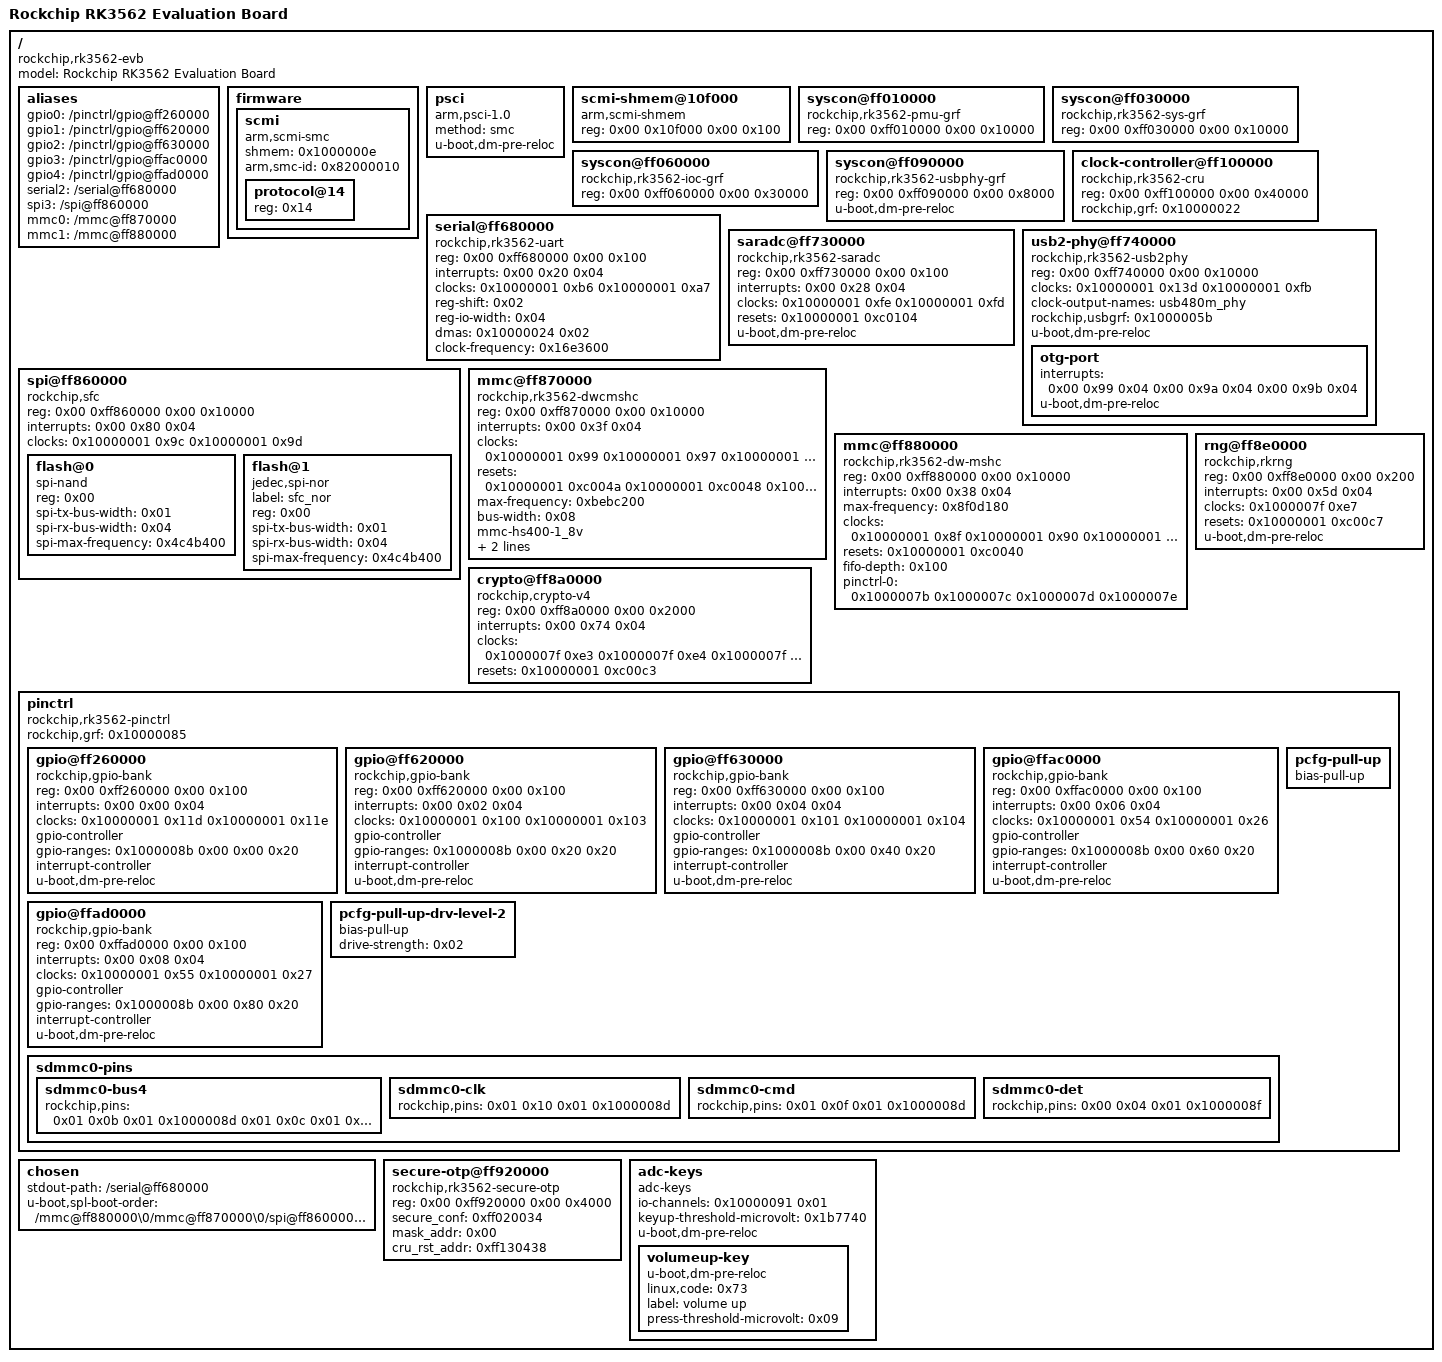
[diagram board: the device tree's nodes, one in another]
/dts-v1/;

/ {
	compatible = "rockchip,rk3562-evb\0rockchip,rk3562";
	#address-cells = <0x02>;
	#size-cells = <0x02>;
	model = "Rockchip RK3562 Evaluation Board";

	aliases {
		gpio0 = "/pinctrl/gpio@ff260000";
		gpio1 = "/pinctrl/gpio@ff620000";
		gpio2 = "/pinctrl/gpio@ff630000";
		gpio3 = "/pinctrl/gpio@ffac0000";
		gpio4 = "/pinctrl/gpio@ffad0000";
		serial2 = "/serial@ff680000";
		spi3 = "/spi@ff860000";
		mmc0 = "/mmc@ff870000";
		mmc1 = "/mmc@ff880000";
	};

	firmware {
		u-boot,dm-spl;

		scmi {
			compatible = "arm,scmi-smc";
			shmem = <0x1000000e>;
			arm,smc-id = <0x82000010>;
			#address-cells = <0x01>;
			#size-cells = <0x00>;
			u-boot,dm-spl;

			protocol@14 {
				reg = <0x14>;
				#clock-cells = <0x01>;
				u-boot,dm-spl;
				phandle = <0x1000007f>;
			};
		};
	};

	psci {
		compatible = "arm,psci-1.0";
		method = "smc";
		u-boot,dm-pre-reloc;
		status = "okay";
	};

	scmi-shmem@10f000 {
		compatible = "arm,scmi-shmem";
		reg = <0x00 0x10f000 0x00 0x100>;
		u-boot,dm-spl;
		phandle = <0x1000000e>;
	};

	syscon@ff010000 {
		compatible = "rockchip,rk3562-pmu-grf\0syscon\0simple-mfd";
		reg = <0x00 0xff010000 0x00 0x10000>;
		u-boot,dm-spl;
		status = "okay";
	};

	syscon@ff030000 {
		compatible = "rockchip,rk3562-sys-grf\0syscon\0simple-mfd";
		reg = <0x00 0xff030000 0x00 0x10000>;
		u-boot,dm-spl;
		status = "okay";
		phandle = <0x10000022>;
	};

	syscon@ff060000 {
		compatible = "rockchip,rk3562-ioc-grf\0syscon";
		reg = <0x00 0xff060000 0x00 0x30000>;
		u-boot,dm-spl;
		status = "okay";
		phandle = <0x10000085>;
	};

	syscon@ff090000 {
		compatible = "rockchip,rk3562-usbphy-grf\0syscon";
		reg = <0x00 0xff090000 0x00 0x8000>;
		u-boot,dm-pre-reloc;
		status = "okay";
		phandle = <0x1000005b>;
	};

	clock-controller@ff100000 {
		compatible = "rockchip,rk3562-cru";
		reg = <0x00 0xff100000 0x00 0x40000>;
		rockchip,grf = <0x10000022>;
		#clock-cells = <0x01>;
		#reset-cells = <0x01>;
		u-boot,dm-spl;
		status = "okay";
		phandle = <0x10000001>;
	};

	serial@ff680000 {
		compatible = "rockchip,rk3562-uart\0snps,dw-apb-uart";
		reg = <0x00 0xff680000 0x00 0x100>;
		interrupts = <0x00 0x20 0x04>;
		clocks = <0x10000001 0xb6 0x10000001 0xa7>;
		reg-shift = <0x02>;
		reg-io-width = <0x04>;
		dmas = <0x10000024 0x02>;
		status = "okay";
		clock-frequency = <0x16e3600>;
		u-boot,dm-spl;
	};

	saradc@ff730000 {
		compatible = "rockchip,rk3562-saradc";
		reg = <0x00 0xff730000 0x00 0x100>;
		interrupts = <0x00 0x28 0x04>;
		#io-channel-cells = <0x01>;
		clocks = <0x10000001 0xfe 0x10000001 0xfd>;
		resets = <0x10000001 0xc0104>;
		reset-names = "saradc-apb";
		status = "okay";
		u-boot,dm-pre-reloc;
		phandle = <0x10000091>;
	};

	usb2-phy@ff740000 {
		compatible = "rockchip,rk3562-usb2phy";
		reg = <0x00 0xff740000 0x00 0x10000>;
		clocks = <0x10000001 0x13d 0x10000001 0xfb>;
		#clock-cells = <0x00>;
		clock-output-names = "usb480m_phy";
		rockchip,usbgrf = <0x1000005b>;
		status = "okay";
		u-boot,dm-pre-reloc;
		phandle = <0x1000001a>;

		otg-port {
			#phy-cells = <0x00>;
			interrupts = <0x00 0x99 0x04 0x00 0x9a 0x04 0x00 0x9b 0x04>;
			interrupt-names = "otg-bvalid\0otg-id\0linestate";
			status = "okay";
			u-boot,dm-pre-reloc;
			phandle = <0x10000017>;
		};
	};

	spi@ff860000 {
		compatible = "rockchip,sfc";
		reg = <0x00 0xff860000 0x00 0x10000>;
		interrupts = <0x00 0x80 0x04>;
		clocks = <0x10000001 0x9c 0x10000001 0x9d>;
		#address-cells = <0x01>;
		#size-cells = <0x00>;
		status = "okay";
		u-boot,dm-spl;

		flash@0 {
			u-boot,dm-spl;
			compatible = "spi-nand";
			reg = <0x00>;
			spi-tx-bus-width = <0x01>;
			spi-rx-bus-width = <0x04>;
			spi-max-frequency = <0x4c4b400>;
		};

		flash@1 {
			u-boot,dm-spl;
			compatible = "jedec,spi-nor";
			label = "sfc_nor";
			reg = <0x00>;
			spi-tx-bus-width = <0x01>;
			spi-rx-bus-width = <0x04>;
			spi-max-frequency = <0x4c4b400>;
		};
	};

	mmc@ff870000 {
		compatible = "rockchip,rk3562-dwcmshc\0rockchip,rk3528-dwcmshc";
		reg = <0x00 0xff870000 0x00 0x10000>;
		interrupts = <0x00 0x3f 0x04>;
		clocks = <0x10000001 0x99 0x10000001 0x97 0x10000001 0x98 0x10000001 0x9a 0x10000001 0x9b>;
		resets = <0x10000001 0xc004a 0x10000001 0xc0048 0x10000001 0xc0049 0x10000001 0xc004b 0x10000001 0xc004c>;
		reset-names = "core\0bus\0axi\0block\0timer";
		max-frequency = <0xbebc200>;
		status = "okay";
		bus-width = <0x08>;
		u-boot,dm-spl;
		mmc-hs400-1_8v;
		mmc-hs400-enhanced-strobe;
		fixed-emmc-driver-type = <0x01>;
	};

	mmc@ff880000 {
		compatible = "rockchip,rk3562-dw-mshc\0rockchip,rk3288-dw-mshc";
		reg = <0x00 0xff880000 0x00 0x10000>;
		interrupts = <0x00 0x38 0x04>;
		max-frequency = <0x8f0d180>;
		clocks = <0x10000001 0x8f 0x10000001 0x90 0x10000001 0x93 0x10000001 0x94>;
		resets = <0x10000001 0xc0040>;
		reset-names = "reset";
		fifo-depth = <0x100>;
		status = "okay";
		u-boot,dm-spl;
		pinctrl-names = "default";
		pinctrl-0 = <0x1000007b 0x1000007c 0x1000007d 0x1000007e>;
	};

	crypto@ff8a0000 {
		compatible = "rockchip,crypto-v4";
		reg = <0x00 0xff8a0000 0x00 0x2000>;
		interrupts = <0x00 0x74 0x04>;
		clocks = <0x1000007f 0xe3 0x1000007f 0xe4 0x1000007f 0xe0 0x1000007f 0xe1 0x1000007f 0xe2>;
		resets = <0x10000001 0xc00c3>;
		reset-names = "crypto-rst";
		status = "okay";
		u-boot,dm-spl;
	};

	rng@ff8e0000 {
		compatible = "rockchip,rkrng";
		reg = <0x00 0xff8e0000 0x00 0x200>;
		interrupts = <0x00 0x5d 0x04>;
		clocks = <0x1000007f 0xe7>;
		resets = <0x10000001 0xc00c7>;
		reset-names = "reset";
		status = "okay";
		u-boot,dm-pre-reloc;
	};

	pinctrl {
		compatible = "rockchip,rk3562-pinctrl";
		rockchip,grf = <0x10000085>;
		#address-cells = <0x02>;
		#size-cells = <0x02>;
		ranges;
		u-boot,dm-spl;
		status = "okay";
		phandle = <0x1000008b>;

		gpio@ff260000 {
			compatible = "rockchip,gpio-bank";
			reg = <0x00 0xff260000 0x00 0x100>;
			interrupts = <0x00 0x00 0x04>;
			clocks = <0x10000001 0x11d 0x10000001 0x11e>;
			gpio-controller;
			#gpio-cells = <0x02>;
			gpio-ranges = <0x1000008b 0x00 0x00 0x20>;
			interrupt-controller;
			#interrupt-cells = <0x02>;
			u-boot,dm-pre-reloc;
		};

		gpio@ff620000 {
			compatible = "rockchip,gpio-bank";
			reg = <0x00 0xff620000 0x00 0x100>;
			interrupts = <0x00 0x02 0x04>;
			clocks = <0x10000001 0x100 0x10000001 0x103>;
			gpio-controller;
			#gpio-cells = <0x02>;
			gpio-ranges = <0x1000008b 0x00 0x20 0x20>;
			interrupt-controller;
			#interrupt-cells = <0x02>;
			u-boot,dm-pre-reloc;
		};

		gpio@ff630000 {
			compatible = "rockchip,gpio-bank";
			reg = <0x00 0xff630000 0x00 0x100>;
			interrupts = <0x00 0x04 0x04>;
			clocks = <0x10000001 0x101 0x10000001 0x104>;
			gpio-controller;
			#gpio-cells = <0x02>;
			gpio-ranges = <0x1000008b 0x00 0x40 0x20>;
			interrupt-controller;
			#interrupt-cells = <0x02>;
			u-boot,dm-pre-reloc;
		};

		gpio@ffac0000 {
			compatible = "rockchip,gpio-bank";
			reg = <0x00 0xffac0000 0x00 0x100>;
			interrupts = <0x00 0x06 0x04>;
			clocks = <0x10000001 0x54 0x10000001 0x26>;
			gpio-controller;
			#gpio-cells = <0x02>;
			gpio-ranges = <0x1000008b 0x00 0x60 0x20>;
			interrupt-controller;
			#interrupt-cells = <0x02>;
			u-boot,dm-pre-reloc;
		};

		gpio@ffad0000 {
			compatible = "rockchip,gpio-bank";
			reg = <0x00 0xffad0000 0x00 0x100>;
			interrupts = <0x00 0x08 0x04>;
			clocks = <0x10000001 0x55 0x10000001 0x27>;
			gpio-controller;
			#gpio-cells = <0x02>;
			gpio-ranges = <0x1000008b 0x00 0x80 0x20>;
			interrupt-controller;
			#interrupt-cells = <0x02>;
			u-boot,dm-pre-reloc;
		};

		pcfg-pull-up {
			bias-pull-up;
			u-boot,dm-spl;
			status = "okay";
			phandle = <0x1000008f>;
		};

		pcfg-pull-up-drv-level-2 {
			bias-pull-up;
			drive-strength = <0x02>;
			u-boot,dm-spl;
			status = "okay";
			phandle = <0x1000008d>;
		};

		sdmmc0-pins {
			u-boot,dm-spl;

			sdmmc0-bus4 {
				rockchip,pins = <0x01 0x0b 0x01 0x1000008d 0x01 0x0c 0x01 0x1000008d 0x01 0x0d 0x01 0x1000008d 0x01 0x0e 0x01 0x1000008d>;
				u-boot,dm-spl;
				phandle = <0x1000007e>;
			};

			sdmmc0-clk {
				rockchip,pins = <0x01 0x10 0x01 0x1000008d>;
				u-boot,dm-spl;
				phandle = <0x1000007b>;
			};

			sdmmc0-cmd {
				rockchip,pins = <0x01 0x0f 0x01 0x1000008d>;
				u-boot,dm-spl;
				phandle = <0x1000007c>;
			};

			sdmmc0-det {
				rockchip,pins = <0x00 0x04 0x01 0x1000008f>;
				u-boot,dm-spl;
				phandle = <0x1000007d>;
			};
		};
	};

	chosen {
		stdout-path = "/serial@ff680000";
		u-boot,spl-boot-order = "/mmc@ff880000\0/mmc@ff870000\0/spi@ff860000/flash@0\0/spi@ff860000/flash@1";
	};

	secure-otp@ff920000 {
		compatible = "rockchip,rk3562-secure-otp";
		reg = <0x00 0xff920000 0x00 0x4000>;
		secure_conf = <0xff020034>;
		mask_addr = <0x00>;
		cru_rst_addr = <0xff130438>;
		u-boot,dm-spl;
		status = "okay";
	};

	adc-keys {
		compatible = "adc-keys";
		io-channels = <0x10000091 0x01>;
		io-channel-names = "buttons";
		keyup-threshold-microvolt = <0x1b7740>;
		u-boot,dm-pre-reloc;
		status = "okay";

		volumeup-key {
			u-boot,dm-pre-reloc;
			linux,code = <0x73>;
			label = "volume up";
			press-threshold-microvolt = <0x09>;
		};
	};
};
